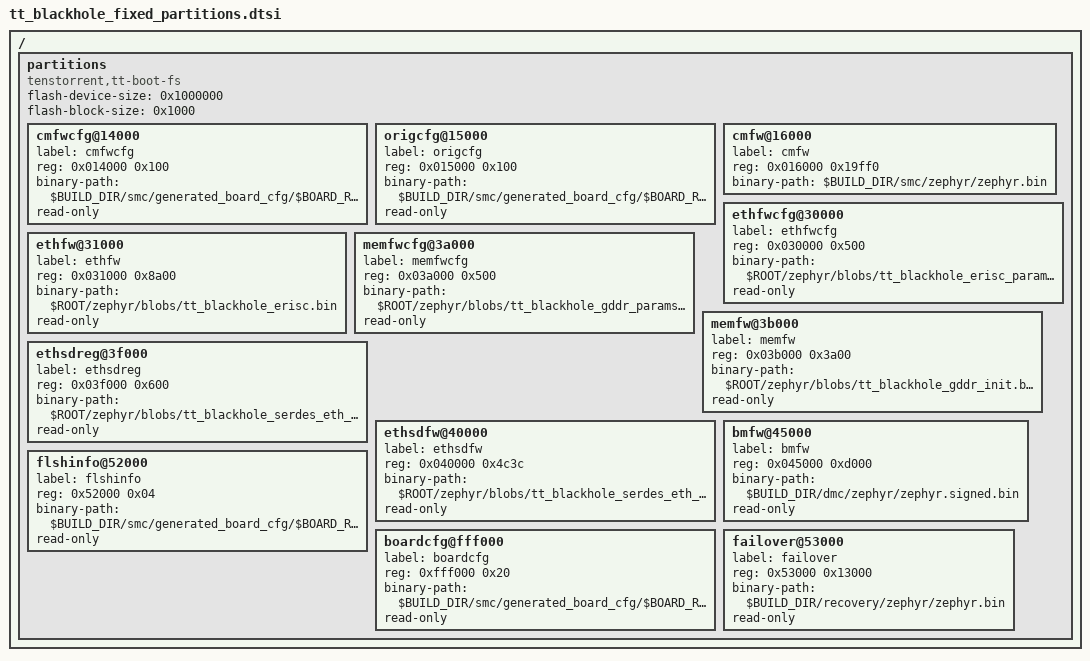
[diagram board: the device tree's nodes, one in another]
/*
 * Copyright (c) 2025 Tenstorrent AI ULC
 *
 * SPDX-License-Identifier: Apache-2.0
 */

/ {
	partitions {
		compatible = "tenstorrent,tt-boot-fs", "fixed-partitions";
		#address-cells = <1>;
		#size-cells = <1>;

		flash-device-size = <0x1000000>;
		flash-block-size = <0x1000>;

		cmfwcfg@14000 {
			label = "cmfwcfg";
			reg = <0x014000 0x100>;
			binary-path = "$BUILD_DIR/smc/generated_board_cfg/$BOARD_REV/fw_table.bin";
			read-only;
		};

		origcfg@15000 {
			label = "origcfg";
			reg = <0x015000 0x100>;
			binary-path = "$BUILD_DIR/smc/generated_board_cfg/$BOARD_REV/fw_table.bin";
			read-only;
		};

		cmfw@16000 {
			label = "cmfw";
			reg = <0x016000 0x19ff0>;
			binary-path = "$BUILD_DIR/smc/zephyr/zephyr.bin";
		};

		ethfwcfg@30000 {
			label = "ethfwcfg";
			reg = <0x030000 0x500>;
			binary-path = "$ROOT/zephyr/blobs/tt_blackhole_erisc_params.bin";
			read-only;
		};

		ethfw@31000 {
			label = "ethfw";
			reg = <0x031000 0x8a00>;
			binary-path = "$ROOT/zephyr/blobs/tt_blackhole_erisc.bin";
			read-only;
		};

		memfwcfg@3a000 {
			label = "memfwcfg";
			reg = <0x03a000 0x500>;
			binary-path = "$ROOT/zephyr/blobs/tt_blackhole_gddr_params_$BOARD_REV.bin";
			read-only;
		};

		memfw@3b000 {
			label = "memfw";
			reg = <0x03b000 0x3a00>;
			binary-path = "$ROOT/zephyr/blobs/tt_blackhole_gddr_init.bin";
			read-only;
		};

		ethsdreg@3f000 {
			label = "ethsdreg";
			reg = <0x03f000 0x600>;
			binary-path = "$ROOT/zephyr/blobs/tt_blackhole_serdes_eth_fwreg.bin";
			read-only;
		};

		ethsdfw@40000 {
			label = "ethsdfw";
			reg = <0x040000 0x4c3c>;
			binary-path = "$ROOT/zephyr/blobs/tt_blackhole_serdes_eth_fw.bin";
			read-only;
		};

		bmfw@45000 {
			label = "bmfw";
			reg = <0x045000 0xd000>;
			binary-path = "$BUILD_DIR/dmc/zephyr/zephyr.signed.bin";
			read-only;
		};

		flshinfo@52000 {
			label = "flshinfo";
			reg = <0x52000 0x04>;
			binary-path =
				"$BUILD_DIR/smc/generated_board_cfg/$BOARD_REV/flash_info.bin";
			read-only;
		};

		boardcfg@fff000 {
			label = "boardcfg";
			reg = <0xfff000 0x20>;
			binary-path = "$BUILD_DIR/smc/generated_board_cfg/$BOARD_REV/read_only.bin";
			read-only;
		};

		failover@53000 {
			label = "failover";
			reg = <0x53000 0x13000>;
			binary-path = "$BUILD_DIR/recovery/zephyr/zephyr.bin";
			read-only;
		};
	};
};
